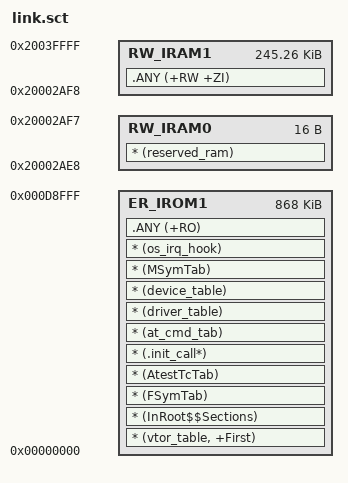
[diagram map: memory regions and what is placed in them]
; *************************************************************
; *** Scatter-Loading Description File generated by uVision ***
; *************************************************************

LR_IROM1 0 0xd9000  {    ; load region size_region
  ER_IROM1 0 0xd9000  {  ; load address = execution address
   * (vtor_table, +First)
   * (InRoot$$Sections)
   * (FSymTab)
   * (AtestTcTab)
   * (.init_call*)
   * (at_cmd_tab)
   * (driver_table)
   * (device_table)
   * (MSymTab)
   * (os_irq_hook)
   .ANY (+RO)
  }

  RW_IRAM0 0x20002ae8 0x10  {  ; RW data
   * (reserved_ram)
  }

  RW_IRAM1 0x20002af8 0x3d508 {  ; RW data
   .ANY (+RW +ZI)
  }
}

